# AM335x register map
Vendor: Texas Instruments; Series: Sitara AM335x; File version: 1.1
AM335x peripherals generated from REGS.hpp
CPU: Cortex-A8 r0p0, little endian
Registers are 32-bit, read-write, reset 0x0 unless marked. A register's access mark holds for its fields unless they carry their own. Offsets are from the block's base; lines under a group give offsets from that group; [hi:lo] are bit positions; {n}, {i} and the like mark numbered series; 'fields as' and 'values as' point back to an identical list; <NAME> marks a mode.

## Memory map
0x44E00000 CM_PER — Clock Module - Peripheral
0x44E00400 CM_WKUP — Clock Module - Wakeup
0x44E00500 CM_DPLL — Clock Module - DPLL
0x44E00600 CM_MPU — Clock Module - MPU
0x44E00700 CM_DEVICE — Clock Module - Device
0x44E00800 CM_RTC — Clock Module - RTC
0x44E00900 CM_GFX — Clock Module - GFX
0x44E00A00 CM_CEFUSE — Clock Module - CEFUSE
0x44E00B00 PRM_IRQ — Power Reset Module - IRQ
0x44E00C00 PRM_PER — Power Reset Module - Peripheral
0x44E00D00 PRM_WKUP — Power Reset Module - Wakeup
0x44E00E00 PRM_MPU — Power Reset Module - MPU
0x44E00F00 PRM_DEVICE — Power Reset Module - Device
0x44E01000 PRM_RTC — Power Reset Module - RTC
0x44E01100 PRM_GFX — Power Reset Module - GFX
0x44E01200 PRM_CEFUSE — Power Reset Module - CEFUSE

## CM_CEFUSE — Clock Module - CEFUSE
Base 0x44E00A00
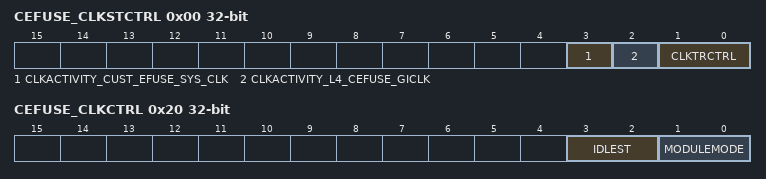
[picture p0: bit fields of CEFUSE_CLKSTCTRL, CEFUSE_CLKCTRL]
0x00 CEFUSE_CLKSTCTRL
  [3] CLKACTIVITY_CUST_EFUSE_SYS_CLK — bit: 9 (R)This field indicates the state of the Cust_Efuse_SYSCLK clock input of the domain.[0x0 = Inact; 0x1 = Act]
  [2] CLKACTIVITY_L4_CEFUSE_GICLK — bit: 8 (R)This field indicates the state of the L4_CEFUSE_GCLK clock input of the domain.[0x0 = Inact; 0x1 = Act]
  [1:0] CLKTRCTRL — bit: 0,1 (RW)Clock state transition [see e_PRCM_CLKTRCTRL]
0x20 CEFUSE_CLKCTRL — CM_CLKCTRL Register
  [3:2] IDLEST — bit: 16,17 (R)Module idle status.[see e_PRCM_IDLEST]
  [1:0] MODULEMODE — bit: 0,1 (RW)Control the way mandatory clocks are managed.[see e_PRCM_MODULEMODE]

## CM_DEVICE — Clock Module - Device
Base 0x44E00700
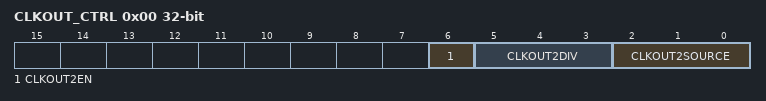
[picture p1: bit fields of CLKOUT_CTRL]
0x00 CLKOUT_CTRL
  [6] CLKOUT2EN — bit: 7 (RW)This bit controls the external clock activity [0x0 = SYS_CLKOUT2 is disabled; 0x1 = SYS_CLKOUT2 is enabled]
  [5:3] CLKOUT2DIV — THis field controls the external clock divison factor [see e_MPU_CLKOUT2DIV]
  [2:0] CLKOUT2SOURCE — This field selects the external output clock source. [see e_MPU_CLKOUT2SOURCE]

## CM_DPLL — Clock Module - DPLL
Base 0x44E00500
0x04 TIMER7_CLK
  [1:0] CLKSEL — bit: 0,1 (RW)Selects the Mux select line for TIMER7 clock[see e_TIMER_CLKSEL]
{0x0+4i} TIMER{i}_CLK (i=2..4)
  [1:0] CLKSEL — bit: 0,1 (RW)Selects the Mux select line for TIMER{i} clock[see e_TIMER_CLKSEL]
0x14 MAC_CLKSEL
  [0] MII_CLK_SEL — bit: 2 (RW)MII Clock Divider Selection.[0x0 = Selects 1/2 divider of SYSCLK2;0x1 = Selects 1/5 divide ratio of SYSCLK2]
0x18 TIMER5_CLK
  [1:0] CLKSEL — bit: 0,1 (RW)Selects the Mux select line for TIMER5 clock[see e_TIMER_CLKSEL]
0x1C TIMER6_CLK
  [1:0] CLKSEL — bit: 0,1 (RW)Selects the Mux select line for TIMER6 clock[see e_TIMER_CLKSEL]
0x20 CPTS_RFT_CLKSEL
  [0] CLKSEL — bit: 0,1 (RW)Selects the Mux select line for cpgmac rft clock [0x0 = Selects CORE_CLKOUTM5;0x1 = Selects CORE_CLKOUTM4]
0x28 TIMER1MS_CLK
  [2:0] CLKSEL — Selects the Mux select line for TIMER1 clock[see e_TIMER1MS_CLKSEL]
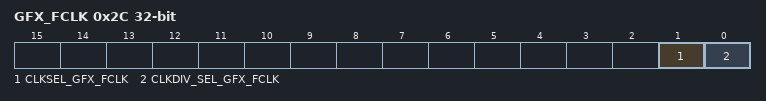
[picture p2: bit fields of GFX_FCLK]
0x2C GFX_FCLK
  [1] CLKSEL_GFX_FCLK — bit: 1 (RW)Selects the clock on gfx fclk [0x0 = from CORE PLL;0x1 = from PER PLL]
  [0] CLKDIV_SEL_GFX_FCLK — bit: 0 (RW)Selects the divider value on gfx fclk [0x0 = L3 Clock or 192MHz Clock; 0x1 =L3 clock/2 or 192Mhz/2]
0x30 PRU_ICSS_OCP_CLK
  [0] CLKSEL — bit: 0,1 (RW)Controls Mux Select of PRU-ICSS OCP clock mux[0x0 = L3F clock as OCP;0x1 = DISP DPLL clock as OCP]
0x34 LCDC_PIXEL_CLK
  [1:0] CLKSEL — bit: 0,1 (RW)Controls the Mux Select of LCDC PIXEL clock[see e_LCDC_PIXEL_CLKSEL]
0x38 WDT1_CLK
  [0] CLKSEL — bit: 0,1 (RW)Selects the Mux select line for WDT1 clock[0x0 = 32KHZ clock from RC Oscillator;0x1 = 32KHZ from 32K Clock divider]
0x3C GPIO0_DBCLK
  [1:0] CLKSEL — bit: 0,1 (RW)Selects the Mux select line for GPIO0 debounce clock[see e_GPIO0_CLKSEL]
